AUTOSAR XML (schema 4-0-3)
package /ComponentTypes
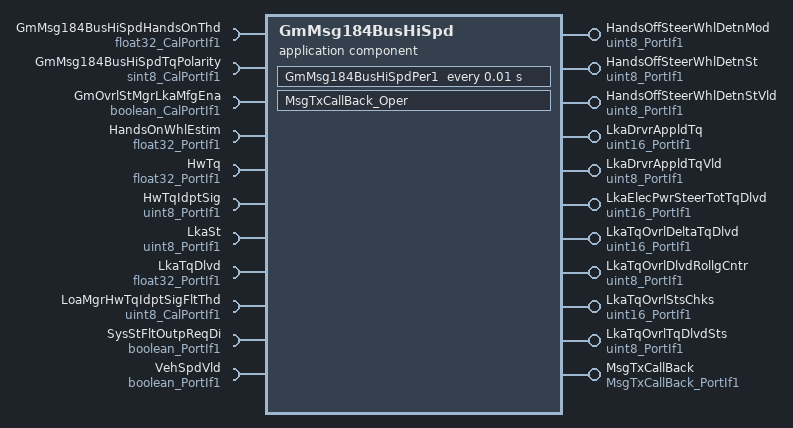
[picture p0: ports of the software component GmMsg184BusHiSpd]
  application sw component type GmMsg184BusHiSpd
    11 x provide port:
      HandsOffSteerWhlDetnMod: nonqueued-sender-com-spec{data-element=Val, init-value=0}, provided-interface=uint8_PortIf1
      HandsOffSteerWhlDetnSt: nonqueued-sender-com-spec{data-element=Val, init-value=0}, provided-interface=uint8_PortIf1
      HandsOffSteerWhlDetnStVld: nonqueued-sender-com-spec{data-element=Val, init-value=0}, provided-interface=uint8_PortIf1
      LkaDrvrAppldTq: nonqueued-sender-com-spec{data-element=Val, init-value=0}, provided-interface=uint16_PortIf1
      LkaDrvrAppldTqVld: nonqueued-sender-com-spec{data-element=Val, init-value=0}, provided-interface=uint8_PortIf1
      LkaElecPwrSteerTotTqDlvd: nonqueued-sender-com-spec{data-element=Val, init-value=0}, provided-interface=uint16_PortIf1
      LkaTqOvrlDeltaTqDlvd: nonqueued-sender-com-spec{data-element=Val, init-value=0}, provided-interface=uint16_PortIf1
      LkaTqOvrlDlvdRollgCntr: nonqueued-sender-com-spec{data-element=Val, init-value=0}, provided-interface=uint8_PortIf1
      LkaTqOvrlStsChks: nonqueued-sender-com-spec{data-element=Val, init-value=0}, provided-interface=uint16_PortIf1
      LkaTqOvrlTqDlvdSts: nonqueued-sender-com-spec{data-element=Val, init-value=0}, provided-interface=uint8_PortIf1
      MsgTxCallBack: server-com-spec{operation=Oper, queue-length=1}, provided-interface=MsgTxCallBack_PortIf1
    11 x require port:
      GmMsg184BusHiSpdHandsOnThd: parameter-require-com-spec{init-value=0.5, parameter=Val}, required-interface=float32_CalPortIf1
      GmMsg184BusHiSpdTqPolarity: parameter-require-com-spec{init-value=1, parameter=Val}, required-interface=sint8_CalPortIf1
      GmOvrlStMgrLkaMfgEna: parameter-require-com-spec{init-value=0, parameter=Logl}, required-interface=boolean_CalPortIf1
      HandsOnWhlEstim: nonqueued-receiver-com-spec{data-element=Val, filter=data-filter-type=ALWAYS, init-value=0}, required-interface=float32_PortIf1
      HwTq: nonqueued-receiver-com-spec{data-element=Val, filter=data-filter-type=ALWAYS, init-value=0}, required-interface=float32_PortIf1
      HwTqIdptSig: nonqueued-receiver-com-spec{data-element=Val, filter=data-filter-type=ALWAYS, init-value=4}, required-interface=uint8_PortIf1
      LkaSt: nonqueued-receiver-com-spec{data-element=Val, filter=data-filter-type=ALWAYS, init-value=0}, required-interface=uint8_PortIf1
      LkaTqDlvd: nonqueued-receiver-com-spec{data-element=Val, filter=data-filter-type=ALWAYS, init-value=0}, required-interface=float32_PortIf1
      LoaMgrHwTqIdptSigFltThd: parameter-require-com-spec{init-value=1, parameter=Val}, required-interface=uint8_CalPortIf1
      SysStFltOutpReqDi: nonqueued-receiver-com-spec{data-element=Logl, filter=data-filter-type=ALWAYS, init-value=0}, required-interface=boolean_PortIf1
      VehSpdVld: nonqueued-receiver-com-spec{data-element=Logl, filter=data-filter-type=ALWAYS, init-value=0}, required-interface=boolean_PortIf1
    behavior GmMsg184BusHiSpd_InternalBehavior: data-type-mapping=Nexteer
      ar-typed-per-instance-memorys:
        data GmMsg184BusHiSpdRollgCntr: sw-calibration-access=READ-ONLY, type=uint8
      timing event TMT_GM0C9HSPer1: start-on-event=GmMsg184BusHiSpdPer1, period=0.01
      operation invoked event OIT_MsgTxCallBack_Oper_MsgTxCallBack_Oper: start-on-event=MsgTxCallBack_Oper, operation=MsgTxCallBack.Oper
      runnable GmMsg184BusHiSpdPer1
        data-receive-point-by-arguments:
          7 x access:
            REC_HandsOnWhlEstim_Val: accessed-variable=HandsOnWhlEstim.Val
            REC_HwTq_Val: accessed-variable=HwTq.Val
            REC_HwTqIdptSig_Val: accessed-variable=HwTqIdptSig.Val
            REC_LkaSt_Val: accessed-variable=LkaSt.Val
            REC_LkaTqDlvd_Val: accessed-variable=LkaTqDlvd.Val
            REC_SysStFltOutpReqDi_Logl: accessed-variable=SysStFltOutpReqDi.Logl
            REC_VehSpdVld_Logl: accessed-variable=VehSpdVld.Logl
        data-send-points:
          10 x access:
            SEND_HandsOffSteerWhlDetnMod_Val: accessed-variable=HandsOffSteerWhlDetnMod.Val
            SEND_HandsOffSteerWhlDetnSt_Val: accessed-variable=HandsOffSteerWhlDetnSt.Val
            SEND_HandsOffSteerWhlDetnStVld_Val: accessed-variable=HandsOffSteerWhlDetnStVld.Val
            SEND_LkaDrvrAppldTq_Val: accessed-variable=LkaDrvrAppldTq.Val
            SEND_LkaDrvrAppldTqVld_Val: accessed-variable=LkaDrvrAppldTqVld.Val
            SEND_LkaElecPwrSteerTotTqDlvd_Val: accessed-variable=LkaElecPwrSteerTotTqDlvd.Val
            SEND_LkaTqOvrlDeltaTqDlvd_Val: accessed-variable=LkaTqOvrlDeltaTqDlvd.Val
            SEND_LkaTqOvrlDlvdRollgCntr_Val: accessed-variable=LkaTqOvrlDlvdRollgCntr.Val
            SEND_LkaTqOvrlStsChks_Val: accessed-variable=LkaTqOvrlStsChks.Val
            SEND_LkaTqOvrlTqDlvdSts_Val: accessed-variable=LkaTqOvrlTqDlvdSts.Val
      runnable MsgTxCallBack_Oper
  swc implementation GmMsg184BusHiSpd_Implementation: behavior=GmMsg184BusHiSpd_InternalBehavior
    code-descriptors:
      code Default: artifact-descriptors=autosar-engineering-object={short-label=Default, category=SWSRC}
